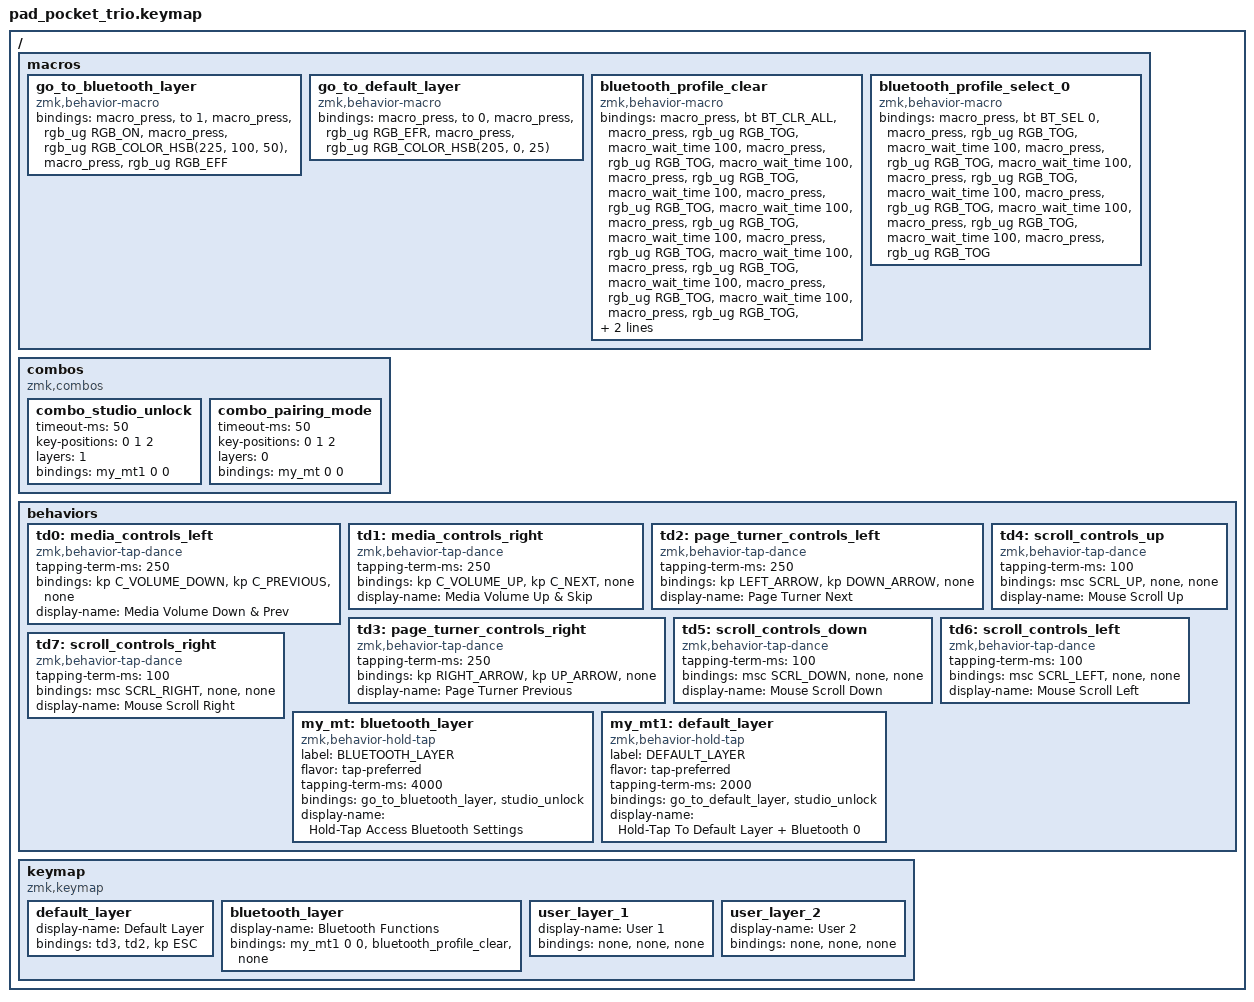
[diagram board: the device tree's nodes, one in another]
#include <behaviors.dtsi>
#include <dt-bindings/zmk/keys.h>
#include <dt-bindings/zmk/bt.h>
#include <dt-bindings/zmk/rgb.h>
#include <dt-bindings/zmk/pointing.h>

/ {
     macros {
        go_to_bluetooth_layer: go_to_bluetooth_layer {
            compatible = "zmk,behavior-macro";
            #binding-cells = <0>;
            bindings = <&macro_press &to 1>, <&macro_press &rgb_ug RGB_ON>, <&macro_press &rgb_ug RGB_COLOR_HSB(225, 100, 50)>, <&macro_press &rgb_ug RGB_EFF>; 
        };

        go_to_default_layer: go_to_default_layer {
            compatible = "zmk,behavior-macro";
            #binding-cells = <0>;
            bindings = <&macro_press &to 0>, <&macro_press &rgb_ug RGB_EFR>, <&macro_press &rgb_ug RGB_COLOR_HSB(205, 0, 25)>; 
        };

        bluetooth_profile_clear: bluetooth_profile_clear {
            compatible = "zmk,behavior-macro";
            #binding-cells = <0>;
            bindings = <&macro_press &bt BT_CLR_ALL>
            , <&macro_press &rgb_ug RGB_TOG>
            , <&macro_wait_time 100>
            , <&macro_press &rgb_ug RGB_TOG>
            ,  <&macro_wait_time 100>
            , <&macro_press &rgb_ug RGB_TOG>
            , <&macro_wait_time 100>
            , <&macro_press &rgb_ug RGB_TOG>
            , <&macro_wait_time 100>
            , <&macro_press &rgb_ug RGB_TOG>
            , <&macro_wait_time 100>
            , <&macro_press &rgb_ug RGB_TOG>
            , <&macro_wait_time 100>
            , <&macro_press &rgb_ug RGB_TOG>
            , <&macro_wait_time 100>
            , <&macro_press &rgb_ug RGB_TOG>
            , <&macro_wait_time 100>
            , <&macro_press &rgb_ug RGB_TOG>
            , <&macro_wait_time 100>
            , <&macro_press &rgb_ug RGB_TOG>; 
        };

        bluetooth_profile_select_0: bluetooth_profile_select_0 {
            compatible = "zmk,behavior-macro";
            #binding-cells = <0>;
            bindings = <&macro_press &bt BT_SEL 0>
            , <&macro_press &rgb_ug RGB_TOG>
            , <&macro_wait_time 100>
            , <&macro_press &rgb_ug RGB_TOG>
            , <&macro_wait_time 100>
            , <&macro_press &rgb_ug RGB_TOG>
            , <&macro_wait_time 100>
            , <&macro_press &rgb_ug RGB_TOG>
            , <&macro_wait_time 100>
            , <&macro_press &rgb_ug RGB_TOG>
            , <&macro_wait_time 100>
            , <&macro_press &rgb_ug RGB_TOG>; 
        };
    };

    combos {
        compatible = "zmk,combos";
        combo_studio_unlock {
            timeout-ms = <50>;
            key-positions = <0 1 2>;
            layers = <1>;
            bindings = <&my_mt1 0 0>;
        };

        combo_pairing_mode {
            timeout-ms = <50>;
            key-positions = <0 1 2>;
            layers = <0>;
            bindings = <&my_mt 0 0>;
        };
    };

    behaviors {
        td0: media_controls_left {
            compatible = "zmk,behavior-tap-dance";
            #binding-cells = <0>;
            tapping-term-ms = <250>;
            bindings = <&kp C_VOLUME_DOWN>, <&kp C_PREVIOUS>, <&none>;
            display-name = "Media Volume Down & Prev";
        };

        td1: media_controls_right {
            compatible = "zmk,behavior-tap-dance";
            #binding-cells = <0>;
            tapping-term-ms = <250>;
            bindings = <&kp C_VOLUME_UP>, <&kp C_NEXT>, <&none>;
            display-name = "Media Volume Up & Skip";
        };

        td2: page_turner_controls_left {
            compatible = "zmk,behavior-tap-dance";
            #binding-cells = <0>;
            tapping-term-ms = <250>;
            bindings = <&kp LEFT_ARROW>, <&kp DOWN_ARROW>, <&none>;
            display-name = "Page Turner Next";
        };

        td3: page_turner_controls_right {
            compatible = "zmk,behavior-tap-dance";
            #binding-cells = <0>;
            tapping-term-ms = <250>;
            bindings = <&kp RIGHT_ARROW>, <&kp UP_ARROW>, <&none>;
            display-name = "Page Turner Previous";
        };

        td4: scroll_controls_up {
            compatible = "zmk,behavior-tap-dance";
            #binding-cells = <0>;
            tapping-term-ms = <100>;
            bindings = <&msc SCRL_UP>, <&none>, <&none>;
            display-name = "Mouse Scroll Up";
        };

        td5: scroll_controls_down {
            compatible = "zmk,behavior-tap-dance";
            #binding-cells = <0>;
            tapping-term-ms = <100>;
            bindings = <&msc SCRL_DOWN>, <&none>, <&none>;
            display-name = "Mouse Scroll Down";
        };

        td6: scroll_controls_left {
            compatible = "zmk,behavior-tap-dance";
            #binding-cells = <0>;
            tapping-term-ms = <100>;
            bindings = <&msc SCRL_LEFT>, <&none>, <&none>;
            display-name = "Mouse Scroll Left";
        };

        td7: scroll_controls_right {
            compatible = "zmk,behavior-tap-dance";
            #binding-cells = <0>;
            tapping-term-ms = <100>;
            bindings = <&msc SCRL_RIGHT>, <&none>, <&none>;
            display-name = "Mouse Scroll Right";
        };

        my_mt: bluetooth_layer {
            compatible = "zmk,behavior-hold-tap";
            label = "BLUETOOTH_LAYER";
            #binding-cells = <2>;
            flavor = "tap-preferred";
            tapping-term-ms = <4000>;
            bindings = <&go_to_bluetooth_layer>, <&studio_unlock>;
            display-name = "Hold-Tap Access Bluetooth Settings";
        };

        my_mt1: default_layer {
            compatible = "zmk,behavior-hold-tap";
            label = "DEFAULT_LAYER";
            #binding-cells = <2>;
            flavor = "tap-preferred";
            tapping-term-ms = <2000>;
            bindings = <&go_to_default_layer>, <&studio_unlock>;
            display-name = "Hold-Tap To Default Layer + Bluetooth 0";
        };
    };

    keymap {
        compatible = "zmk,keymap";

        default_layer { // Layer 0
            display-name = "Default Layer";
            // -------------------------------------
            //       |     Page Turner Next    |     Page Turner Prev     | Esc
            bindings = <
                &td3
                &td2
                &kp ESC
            >;
        };

        bluetooth_layer { // Layer 1
            display-name = "Bluetooth Functions";
            // -------------------------------------
            //       |     Studio Unlock     |     Clear Bluetooth Profiles    |
            bindings = <
                &my_mt1 0 0
                &bluetooth_profile_clear
                &none
            >;
        };

        user_layer_1 { // Layer 2
            display-name = "User 1";
            // -------------------------------------
            //       |     None     |     None     |
            bindings = <
                &none
                &none
                &none
            >;
        };

        user_layer_2 { // Layer 3
            display-name = "User 2";
            // -------------------------------------
            //       |     None     |     None     |
            bindings = <
                &none
                &none
                &none
            >;
        };
    };
 };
